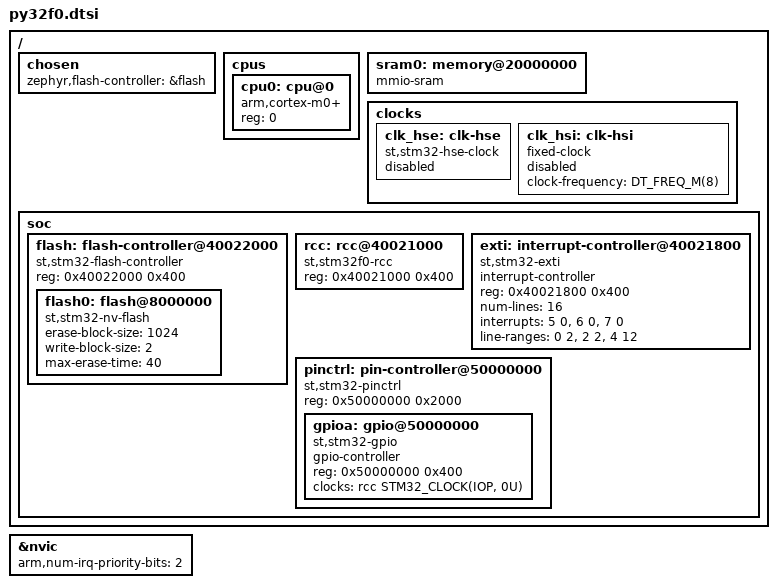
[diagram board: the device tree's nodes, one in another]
/*
 * Copyright (c) 2017 RnDity Sp. z o.o.
 * Copyright (c) 2019 Centaur Analytics, Inc
 * Copyright (c) 2024 STMicroelectronics
 *
 * SPDX-License-Identifier: Apache-2.0
 */

#include <arm/armv6-m.dtsi>
#include <zephyr/dt-bindings/clock/stm32g0_clock.h>
#include <zephyr/dt-bindings/i2c/i2c.h>
#include <zephyr/dt-bindings/gpio/gpio.h>
#include <zephyr/dt-bindings/pwm/pwm.h>
#include <zephyr/dt-bindings/reset/stm32f0_1_3_reset.h>
#include <zephyr/dt-bindings/adc/adc.h>
#include <freq.h>

/ {
	chosen {
		zephyr,flash-controller = &flash;
	};

	cpus {
		#address-cells = <1>;
		#size-cells = <0>;

		cpu0: cpu@0 {
			device_type = "cpu";
			compatible = "arm,cortex-m0+";
			reg = <0>;
		};
	};

	sram0: memory@20000000 {
		compatible = "mmio-sram";
	};

	clocks {
		clk_hse: clk-hse {
			#clock-cells = <0>;
			compatible = "st,stm32-hse-clock";
			status = "disabled";
		};

		clk_hsi: clk-hsi {
			#clock-cells = <0>;
			compatible = "fixed-clock";
			clock-frequency = <DT_FREQ_M(8)>;
			status = "enabled";
		};

	};

	soc {
		flash: flash-controller@40022000 {
			compatible = "st,stm32-flash-controller", "st,stm32f1-flash-controller";
			reg = <0x40022000 0x400>;
			#address-cells = <1>;
			#size-cells = <1>;

			flash0: flash@8000000 {
				compatible = "st,stm32-nv-flash", "soc-nv-flash";
				erase-block-size = <1024>;
				write-block-size = <2>;
				/* maximum erase time for a 2K sector */
				max-erase-time = <40>;
			};
		};

		rcc: rcc@40021000 {
			compatible = "st,stm32f0-rcc";
			#clock-cells = <2>;
			reg = <0x40021000 0x400>;
			status = "okay";
		};

		exti: interrupt-controller@40021800 {
			compatible = "st,stm32-exti";
			interrupt-controller;
			#interrupt-cells = <1>;
			#address-cells = <1>;
			reg = <0x40021800 0x400>;
			num-lines = <16>;
			interrupts = <5 0>, <6 0>, <7 0>;
			interrupt-names = "line0-1", "line2-3", "line4-15";
			line-ranges = <0 2>, <2 2>, <4 12>;
		};

		pinctrl: pin-controller@50000000 {
			compatible = "st,stm32-pinctrl";
			#address-cells = <1>;
			#size-cells = <1>;
			reg = <0x50000000 0x2000>;

			gpioa: gpio@50000000 {
				compatible = "st,stm32-gpio";
				gpio-controller;
				#gpio-cells = <2>;
				reg = <0x50000000 0x400>;
				clocks = <&rcc STM32_CLOCK(IOP, 0U)>;
			};
		};
	};
};

&nvic {
	arm,num-irq-priority-bits = <2>;
};
